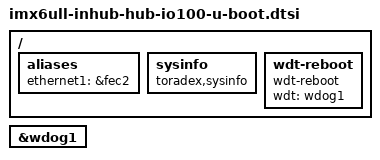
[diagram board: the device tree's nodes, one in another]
// SPDX-License-Identifier: GPL-2.0-only
/*
 * Copyright 2025 in.hub GmbH
 */

/ {
	aliases {
		bootph-all;
		ethernet1 = &fec2;
	};

	sysinfo {
		compatible = "toradex,sysinfo";
	};

	wdt-reboot {
		compatible = "wdt-reboot";
		wdt = <&wdog1>;
		bootph-pre-ram;
	};
};

&wdog1 {
	bootph-pre-ram;
};
